VERSION ""

NS_ :

BS_:

BU_: VCU BMS MCU

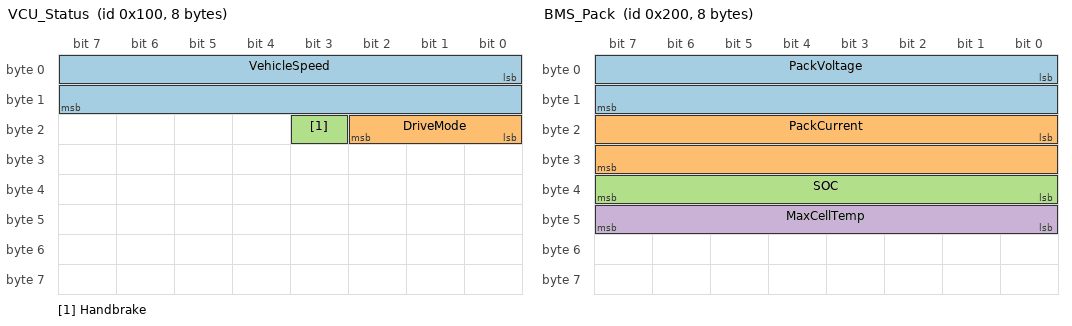
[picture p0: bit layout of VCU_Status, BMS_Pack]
BO_ 256 VCU_Status: 8 VCU
 SG_ VehicleSpeed : 0|16@1+ (0.01,0) [0|120] "km/h" Vector__XXX
 SG_ DriveMode : 16|3@1+ (1,0) [0|4] "" Vector__XXX
 SG_ Handbrake : 19|1@1+ (1,0) [0|1] "" Vector__XXX

BO_ 512 BMS_Pack: 8 BMS
 SG_ PackVoltage : 0|16@1+ (0.01,0) [0|90] "V" Vector__XXX
 SG_ PackCurrent : 16|16@1- (0.1,0) [-200|300] "A" Vector__XXX
 SG_ SOC : 32|8@1+ (0.5,0) [0|100] "%" Vector__XXX
 SG_ MaxCellTemp : 40|8@1+ (1,-40) [-40|80] "degC" Vector__XXX

BO_ 768 Motor_Status: 8 MCU
 SG_ MotorRPM : 0|16@1- (1,0) [-6000|6000] "rpm" Vector__XXX
 SG_ MotorTorque : 16|16@1- (0.1,0) [-150|150] "Nm" Vector__XXX

BA_DEF_ BO_ "GenMsgCycleTime" INT 0 65535;
BA_DEF_DEF_ "GenMsgCycleTime" 0;
BA_ "GenMsgCycleTime" BO_ 256 100;
BA_ "GenMsgCycleTime" BO_ 512 100;
BA_ "GenMsgCycleTime" BO_ 768 50;

VAL_ 256 DriveMode 0 "NEUTRAL" 1 "ECO" 2 "BOOST" 3 "REVERSE";
